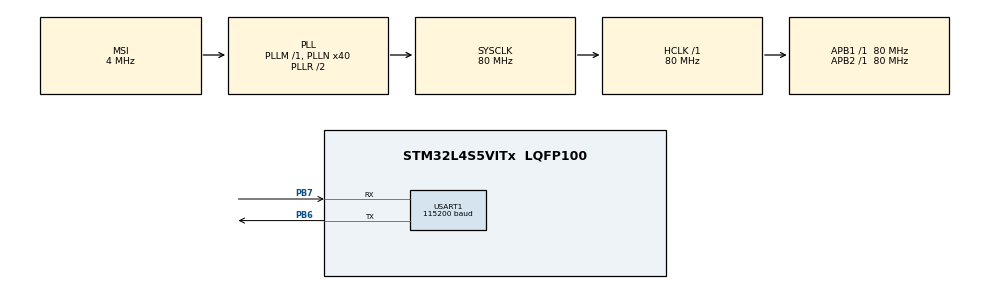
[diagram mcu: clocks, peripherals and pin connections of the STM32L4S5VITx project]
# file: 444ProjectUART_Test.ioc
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Mcu.Family=STM32L4
Mcu.Name=STM32L4S5VITx
Mcu.Package=LQFP100
NVIC.PriorityGroup=NVIC_PRIORITYGROUP_4
NVIC.TIM2_IRQn=true\:0\:0\:false\:false\:true\:true\:true
NVIC.USART1_IRQn=true\:0\:0\:false\:false\:true\:true\:true
PB6.Mode=Asynchronous
PB6.Signal=USART1_TX
PB7.Mode=Asynchronous
PB7.Signal=USART1_RX
ProjectManager.HeapSize=0x200
ProjectManager.StackSize=0x400
ProjectManager.TargetToolchain=STM32CubeIDE
RCC.AHBFreq_Value=80000000
RCC.APB1Freq_Value=80000000
RCC.APB1TimFreq_Value=80000000
RCC.APB2Freq_Value=80000000
RCC.APB2TimFreq_Value=80000000
RCC.CortexFreq_Value=80000000
RCC.HCLKFreq_Value=80000000
RCC.HSE_VALUE=8000000
RCC.HSI48_VALUE=48000000
RCC.HSI_VALUE=16000000
RCC.LSE_VALUE=32768
RCC.MSI_VALUE=4000000
RCC.PLLN=40
RCC.SYSCLKFreq_VALUE=80000000
RCC.SYSCLKSource=RCC_SYSCLKSOURCE_PLLCLK
RCC.VCOOutputFreq_Value=160000000
TIM2.Period=40000000
USART1.AutoBaudRateEnableParam=UART_ADVFEATURE_AUTOBAUDRATE_DISABLE
USART1.BaudRate=115200
USART1.DMADisableonRxErrorParam=ADVFEATURE_DMA_ENABLEONRXERROR
USART1.FIFOMode=FIFOMODE_DISABLE
USART1.OverSampling=UART_OVERSAMPLING_16
USART1.Parity=PARITY_NONE
USART1.VirtualMode-Asynchronous=VM_ASYNC
USART1.WordLength=WORDLENGTH_8B
VP_TIM2_VS_ClockSourceINT.Mode=Internal
board=custom

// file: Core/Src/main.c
/* USER CODE BEGIN Header */
/**
  ******************************************************************************
  * @file           : main.c
  * @brief          : Main program body
  ******************************************************************************
  * @attention
  *
  * <h2><center>&copy; Copyright (c) 2021 STMicroelectronics.
  * All rights reserved.</center></h2>
  *
  * This software component is licensed by ST under BSD 3-Clause license,
  * the "License"; You may not use this file except in compliance with the
  * License. You may obtain a copy of the License at:
  *                        opensource.org/licenses/BSD-3-Clause
  *
  ******************************************************************************
  */
/* USER CODE END Header */
#include "main.h"

/* USER CODE BEGIN Includes */
//############################################################################################################################################

#include "stdlib.h" //For random number generator

//############################################################################################################################################
/* USER CODE END Includes */

/* USER CODE BEGIN PM */
//############################################################################################################################################

#define ASCII_ESC 27

//############################################################################################################################################
/* USER CODE END PM */

TIM_HandleTypeDef htim2;

UART_HandleTypeDef huart1;

void SystemClock_Config(void);
static void MX_GPIO_Init(void);
static void MX_USART1_UART_Init(void);
static void MX_TIM2_Init(void);

/* USER CODE BEGIN 0 */
//############################################################################################################################################

char screen[259];
char title[70];
char liveToneAndGoal[70];
uint8_t receivedKey;
int potentialPoints = 0;

//Clear screen function
void screenClear() {
	char buffer[5];

	sprintf(buffer, "%c[2J", ASCII_ESC);
	HAL_UART_Transmit(&huart1, &buffer, sizeof(buffer), HAL_MAX_DELAY);
}

//Make cursor invisible
void invisibleCursor() {
	char buffer[6];

	sprintf(buffer, "%c[?25l", ASCII_ESC);
	HAL_UART_Transmit(&huart1, &buffer, sizeof(buffer), HAL_MAX_DELAY);
}

//Print welcome screen
void printWelcomeScreen() {
	sprintf(title, "                         Welcome To Karaoke!                          "); //70 long
	sprintf(screen, "\r//////////////////////////////////////////////////////////////////////////\r\n//%s//\r\n//////////////////////////////////////////////////////////////////////////\r\n\n\nPress any key to continue...", title);
	HAL_UART_Transmit(&huart1, &screen, sizeof(screen), HAL_MAX_DELAY);
}

//Print the game starting screen
void printGame(int goalTonePeriod, int voiceTonePeriod, int score) {

	screenClear();

	sprintf(liveToneAndGoal, "                                                                      "); //70 long

	liveToneAndGoal[goalTonePeriod] = 'I';
	liveToneAndGoal[voiceTonePeriod] = 'I';

	sprintf(screen, "\r//////////////////////////////////////////////////////////////////////////\r\n//%s//\r\n//////////////////////////////////////////////////////////////////////////\r\n\n\n\t+---\tSCORE:\t%d\t---+        ", liveToneAndGoal, score);
	HAL_UART_Transmit(&huart1, &screen, sizeof(screen), HAL_MAX_DELAY);
}

//Timer callback
void HAL_TIM_PeriodElapsedCallback(TIM_HandleTypeDef *htim) {
	if (htim == &htim2) {
		if (potentialPoints > 0) potentialPoints = potentialPoints - 1;
	}
}

//############################################################################################################################################
/* USER CODE END 0 */

int main(void)
{

  /* MCU Configuration--------------------------------------------------------*/

  /* Reset of all peripherals, Initializes the Flash interface and the Systick. */
  HAL_Init();

  /* Configure the system clock */
  SystemClock_Config();

  /* Initialize all configured peripherals */
  MX_GPIO_Init();
  MX_USART1_UART_Init();
  MX_TIM2_Init();
  /* USER CODE BEGIN 2 */
//############################################################################################################################################

  invisibleCursor();

  screenClear(); //Start with fresh screen

  printWelcomeScreen();

  HAL_UART_Receive(&huart1, &receivedKey, 1, HAL_MAX_DELAY); //Wait for key press before starting game

  screenClear();

  int success = 1; //Create first goal tone period
  int goalTonePeriod;
  int voiceTonePeriod;
  int score = 0;

  HAL_TIM_Base_Start_IT(&htim2);

//############################################################################################################################################
  /* USER CODE END 2 */

  /* Infinite loop */
  /* USER CODE BEGIN WHILE */
  //############################################################################################################################################

  while (1)
  {
	  if (success) {
		  goalTonePeriod = rand()%66;
		  voiceTonePeriod = 0;
		  score = score + potentialPoints;
		  potentialPoints = 10;
		  success = 0;
	  }

	  printGame(goalTonePeriod, voiceTonePeriod, score);

	  if (goalTonePeriod == voiceTonePeriod) success = 1;

	  voiceTonePeriod = (voiceTonePeriod + 1)%66;

	  HAL_Delay(100);

	  //############################################################################################################################################
    /* USER CODE END WHILE */

  }
}

void SystemClock_Config(void)
{
  RCC_OscInitTypeDef RCC_OscInitStruct = {0};
  RCC_ClkInitTypeDef RCC_ClkInitStruct = {0};
  RCC_PeriphCLKInitTypeDef PeriphClkInit = {0};

  /** Configure the main internal regulator output voltage
  */
  if (HAL_PWREx_ControlVoltageScaling(PWR_REGULATOR_VOLTAGE_SCALE1) != HAL_OK)
  {
    Error_Handler();
  }
  /** Initializes the RCC Oscillators according to the specified parameters
  * in the RCC_OscInitTypeDef structure.
  */
  RCC_OscInitStruct.OscillatorType = RCC_OSCILLATORTYPE_MSI;
  RCC_OscInitStruct.MSIState = RCC_MSI_ON;
  RCC_OscInitStruct.MSICalibrationValue = 0;
  RCC_OscInitStruct.MSIClockRange = RCC_MSIRANGE_6;
  RCC_OscInitStruct.PLL.PLLState = RCC_PLL_ON;
  RCC_OscInitStruct.PLL.PLLSource = RCC_PLLSOURCE_MSI;
  RCC_OscInitStruct.PLL.PLLM = 1;
  RCC_OscInitStruct.PLL.PLLN = 40;
  RCC_OscInitStruct.PLL.PLLP = RCC_PLLP_DIV2;
  RCC_OscInitStruct.PLL.PLLQ = RCC_PLLQ_DIV2;
  RCC_OscInitStruct.PLL.PLLR = RCC_PLLR_DIV2;
  if (HAL_RCC_OscConfig(&RCC_OscInitStruct) != HAL_OK)
  {
    Error_Handler();
  }
  /** Initializes the CPU, AHB and APB buses clocks
  */
  RCC_ClkInitStruct.ClockType = RCC_CLOCKTYPE_HCLK|RCC_CLOCKTYPE_SYSCLK
                              |RCC_CLOCKTYPE_PCLK1|RCC_CLOCKTYPE_PCLK2;
  RCC_ClkInitStruct.SYSCLKSource = RCC_SYSCLKSOURCE_PLLCLK;
  RCC_ClkInitStruct.AHBCLKDivider = RCC_SYSCLK_DIV1;
  RCC_ClkInitStruct.APB1CLKDivider = RCC_HCLK_DIV1;
  RCC_ClkInitStruct.APB2CLKDivider = RCC_HCLK_DIV1;

  if (HAL_RCC_ClockConfig(&RCC_ClkInitStruct, FLASH_LATENCY_3) != HAL_OK)
  {
    Error_Handler();
  }
  PeriphClkInit.PeriphClockSelection = RCC_PERIPHCLK_USART1;
  PeriphClkInit.Usart1ClockSelection = RCC_USART1CLKSOURCE_PCLK2;
  if (HAL_RCCEx_PeriphCLKConfig(&PeriphClkInit) != HAL_OK)
  {
    Error_Handler();
  }
}

static void MX_TIM2_Init(void)
{

  TIM_ClockConfigTypeDef sClockSourceConfig = {0};
  TIM_MasterConfigTypeDef sMasterConfig = {0};

  htim2.Instance = TIM2;
  htim2.Init.Prescaler = 0;
  htim2.Init.CounterMode = TIM_COUNTERMODE_UP;
  htim2.Init.Period = 40000000;
  htim2.Init.ClockDivision = TIM_CLOCKDIVISION_DIV1;
  htim2.Init.AutoReloadPreload = TIM_AUTORELOAD_PRELOAD_DISABLE;
  if (HAL_TIM_Base_Init(&htim2) != HAL_OK)
  {
    Error_Handler();
  }
  sClockSourceConfig.ClockSource = TIM_CLOCKSOURCE_INTERNAL;
  if (HAL_TIM_ConfigClockSource(&htim2, &sClockSourceConfig) != HAL_OK)
  {
    Error_Handler();
  }
  sMasterConfig.MasterOutputTrigger = TIM_TRGO_RESET;
  sMasterConfig.MasterSlaveMode = TIM_MASTERSLAVEMODE_DISABLE;
  if (HAL_TIMEx_MasterConfigSynchronization(&htim2, &sMasterConfig) != HAL_OK)
  {
    Error_Handler();
  }

}

static void MX_USART1_UART_Init(void)
{

  huart1.Instance = USART1;
  huart1.Init.BaudRate = 115200;
  huart1.Init.WordLength = UART_WORDLENGTH_8B;
  huart1.Init.StopBits = UART_STOPBITS_1;
  huart1.Init.Parity = UART_PARITY_NONE;
  huart1.Init.Mode = UART_MODE_TX_RX;
  huart1.Init.HwFlowCtl = UART_HWCONTROL_NONE;
  huart1.Init.OverSampling = UART_OVERSAMPLING_16;
  huart1.Init.OneBitSampling = UART_ONE_BIT_SAMPLE_DISABLE;
  huart1.Init.ClockPrescaler = UART_PRESCALER_DIV1;
  huart1.AdvancedInit.AdvFeatureInit = UART_ADVFEATURE_NO_INIT;
  if (HAL_UART_Init(&huart1) != HAL_OK)
  {
    Error_Handler();
  }
  if (HAL_UARTEx_SetTxFifoThreshold(&huart1, UART_TXFIFO_THRESHOLD_1_8) != HAL_OK)
  {
    Error_Handler();
  }
  if (HAL_UARTEx_SetRxFifoThreshold(&huart1, UART_RXFIFO_THRESHOLD_1_8) != HAL_OK)
  {
    Error_Handler();
  }
  if (HAL_UARTEx_DisableFifoMode(&huart1) != HAL_OK)
  {
    Error_Handler();
  }

}

static void MX_GPIO_Init(void)
{

  /* GPIO Ports Clock Enable */
  __HAL_RCC_GPIOB_CLK_ENABLE();

}

void Error_Handler(void)
{
  __disable_irq();
  while (1)
  {
  }
}

/************************ (C) COPYRIGHT STMicroelectronics *****END OF FILE****/
